AUTOSAR XML (schema 00046)
package /TestAppSWC_package
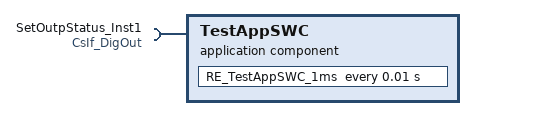
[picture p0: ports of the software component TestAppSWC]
  application sw component type TestAppSWC
    require port SetOutpStatus_Inst1: client-com-spec=CsIf_DigOut_SetSt, required-interface=CsIf_DigOut
    behavior TestAppSWC_internal_behavior
      timing event Periodic_Event_1_event: start-on-event=RE_TestAppSWC_1ms, period=0.01
      runnable RE_TestAppSWC_1ms
